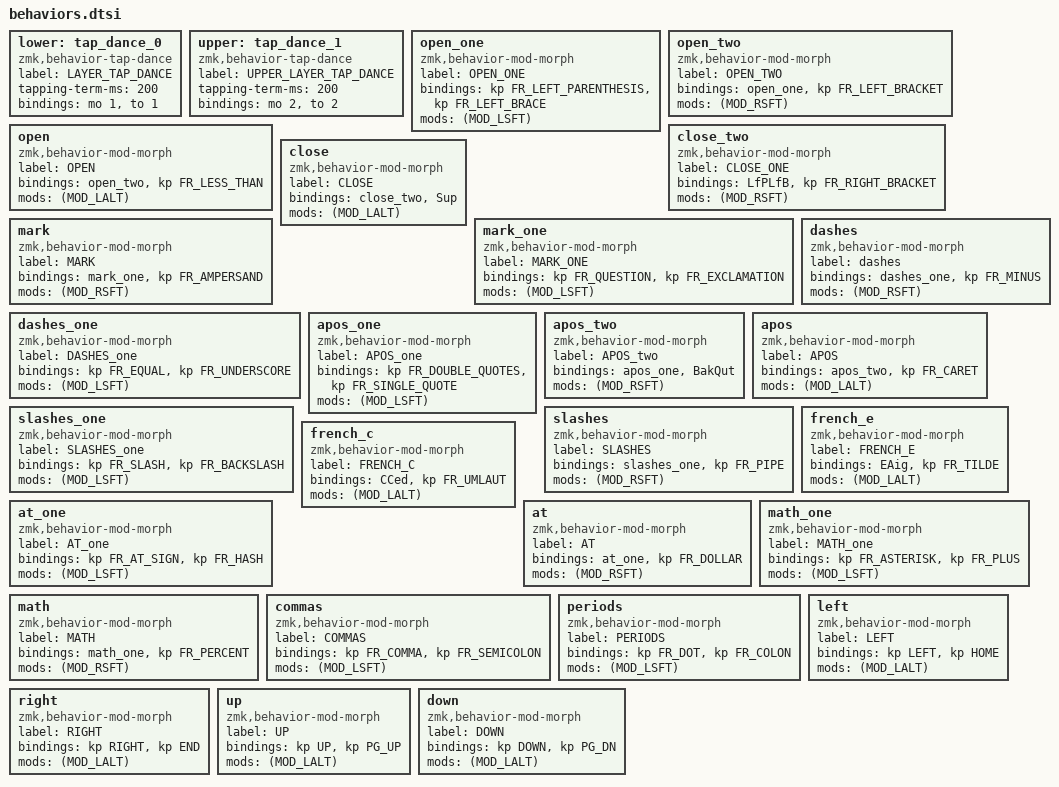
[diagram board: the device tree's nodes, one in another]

// hold or toggle layer 1   
lower: tap_dance_0 {
    compatible = "zmk,behavior-tap-dance";
    label = "LAYER_TAP_DANCE";
    #binding-cells = <0>;
    tapping-term-ms = <200>;
    bindings = <&mo 1>, <&to 1>;
};

// hold or toggle layer 2
upper: tap_dance_1 {
    compatible = "zmk,behavior-tap-dance";
    label = "UPPER_LAYER_TAP_DANCE";
    #binding-cells = <0>;
    tapping-term-ms = <200>;
    bindings = <&mo 2>, <&to 2>;
};

// key lshift rshift alt
//  (     {     [     <
open_one: open_one {
    compatible = "zmk,behavior-mod-morph";
    label = "OPEN_ONE";
    #binding-cells = <0>;
    bindings = <&kp FR_LEFT_PARENTHESIS>, <&kp FR_LEFT_BRACE>;
    mods = <(MOD_LSFT)>;
};
open_two: open_two {
    compatible = "zmk,behavior-mod-morph";
    label = "OPEN_TWO";
    #binding-cells = <0>;
    bindings = <&open_one>, <&kp FR_LEFT_BRACKET>;
    mods = <(MOD_RSFT)>;
};
open: open {
    compatible = "zmk,behavior-mod-morph";
    label = "OPEN";
    #binding-cells = <0>;
    bindings = <&open_two>, <&kp FR_LESS_THAN>;
    mods = <(MOD_LALT)>;
};

// key lshift rshift alt
//  )     }     ]     >
close_two: close_two {
    compatible = "zmk,behavior-mod-morph";
    label = "CLOSE_ONE";
    #binding-cells = <0>;
    bindings = <&LfPLfB>, <&kp FR_RIGHT_BRACKET>;
    mods = <(MOD_RSFT)>;
};
close: close {
    compatible = "zmk,behavior-mod-morph";
    label = "CLOSE";
    #binding-cells = <0>;
    bindings = <&close_two>, <&Sup>;
    mods = <(MOD_LALT)>;
};

// key lshift rshift alt
//  ?     !     &     
mark_one: mark_one {
    compatible = "zmk,behavior-mod-morph";
    label = "MARK_ONE";
    #binding-cells = <0>;
    bindings = <&kp FR_QUESTION>, <&kp FR_EXCLAMATION>;
    mods = <(MOD_LSFT)>;
};
mark: mark {
    compatible = "zmk,behavior-mod-morph";
    label = "MARK";
    #binding-cells = <0>;
    bindings = <&mark_one>, <&kp FR_AMPERSAND>;
    mods = <(MOD_RSFT)>;
};

// key lshift rshift alt
//  =     _     -     
dashes_one: dashes_one {
    compatible = "zmk,behavior-mod-morph";
    label = "DASHES_one";
    #binding-cells = <0>;
    bindings = <&kp FR_EQUAL>, <&kp FR_UNDERSCORE>;
    mods = <(MOD_LSFT)>;
};
dashes: dashes {
    compatible = "zmk,behavior-mod-morph";
    label = "dashes";
    #binding-cells = <0>;
    bindings = <&dashes_one>, <&kp FR_MINUS>;
    mods = <(MOD_RSFT)>;
};

// key lshift rshift alt
//  "     '     `     ^
apos_one: apos_one {
    compatible = "zmk,behavior-mod-morph";
    label = "APOS_one";
    #binding-cells = <0>;
    bindings = <&kp FR_DOUBLE_QUOTES>, <&kp FR_SINGLE_QUOTE>;
    mods = <(MOD_LSFT)>;
};
apos_two: apos_two {
    compatible = "zmk,behavior-mod-morph";
    label = "APOS_two";
    #binding-cells = <0>;
    bindings = <&apos_one>, <&BakQut>;
    mods = <(MOD_RSFT)>;
};
apos: apos {
    compatible = "zmk,behavior-mod-morph";
    label = "APOS";
    #binding-cells = <0>;
    bindings = <&apos_two>, <&kp FR_CARET>;
    mods = <(MOD_LALT)>;
};

// key lshift rshift alt
//  /     \     |     
slashes_one: slashes_one {
    compatible = "zmk,behavior-mod-morph";
    label = "SLASHES_one";
    #binding-cells = <0>;
    bindings = <&kp FR_SLASH>, <&kp FR_BACKSLASH>;
    mods = <(MOD_LSFT)>;
};
slashes: slashes {
    compatible = "zmk,behavior-mod-morph";
    label = "SLASHES";
    #binding-cells = <0>;
    bindings = <&slashes_one>, <&kp FR_PIPE>;
    mods = <(MOD_RSFT)>;
};

// key lshift rshift alt
//  é                 ~
french_e: french_e {
    compatible = "zmk,behavior-mod-morph";
    label = "FRENCH_E";
    #binding-cells = <0>;
    bindings = <&EAig>, <&kp FR_TILDE>;
    mods = <(MOD_LALT)>;
};

// key lshift rshift alt
//  é                 ¨
french_c: french_c {
    compatible = "zmk,behavior-mod-morph";
    label = "FRENCH_C";
    #binding-cells = <0>;
    bindings = <&CCed>, <&kp FR_UMLAUT>;
    mods = <(MOD_LALT)>;
};

// key lshift rshift alt
//  @     #     $      
at_one: at_one {
    compatible = "zmk,behavior-mod-morph";
    label = "AT_one";
    #binding-cells = <0>;
    bindings = <&kp FR_AT_SIGN>, <&kp FR_HASH>;
    mods = <(MOD_LSFT)>;
};
at: at {
    compatible = "zmk,behavior-mod-morph";
    label = "AT";
    #binding-cells = <0>;
    bindings = <&at_one>, <&kp FR_DOLLAR>;
    mods = <(MOD_RSFT)>;
};

// key lshift rshift alt
//  *     +     %      
math_one: math_one {
    compatible = "zmk,behavior-mod-morph";
    label = "MATH_one";
    #binding-cells = <0>;
    bindings = <&kp FR_ASTERISK>, <&kp FR_PLUS>;
    mods = <(MOD_LSFT)>;
};
math: math {
    compatible = "zmk,behavior-mod-morph";
    label = "MATH";
    #binding-cells = <0>;
    bindings = <&math_one>, <&kp FR_PERCENT>;
    mods = <(MOD_RSFT)>;
};

commas: commas {
    compatible = "zmk,behavior-mod-morph";
    label = "COMMAS";
    #binding-cells = <0>;
    bindings = <&kp FR_COMMA>, <&kp FR_SEMICOLON>;
    mods = <(MOD_LSFT)>;
};
    
periods: periods {
    compatible = "zmk,behavior-mod-morph";
    label = "PERIODS";
    #binding-cells = <0>;
    bindings = <&kp FR_DOT>, <&kp FR_COLON>;
    mods = <(MOD_LSFT)>;
};

left: left {
    compatible = "zmk,behavior-mod-morph";
    label = "LEFT";
    #binding-cells = <0>;
    bindings = <&kp LEFT>, <&kp HOME>;
    mods = <(MOD_LALT)>;
};
    
right: right {
    compatible = "zmk,behavior-mod-morph";
    label = "RIGHT";
    #binding-cells = <0>;
    bindings = <&kp RIGHT>, <&kp END>;
    mods = <(MOD_LALT)>;
};
    
up: up {
    compatible = "zmk,behavior-mod-morph";
    label = "UP";
    #binding-cells = <0>;
    bindings = <&kp UP>, <&kp PG_UP>;
    mods = <(MOD_LALT)>;
};
    
down: down {
    compatible = "zmk,behavior-mod-morph";
    label = "DOWN";
    #binding-cells = <0>;
    bindings = <&kp DOWN>, <&kp PG_DN>;
    mods = <(MOD_LALT)>;
};  
